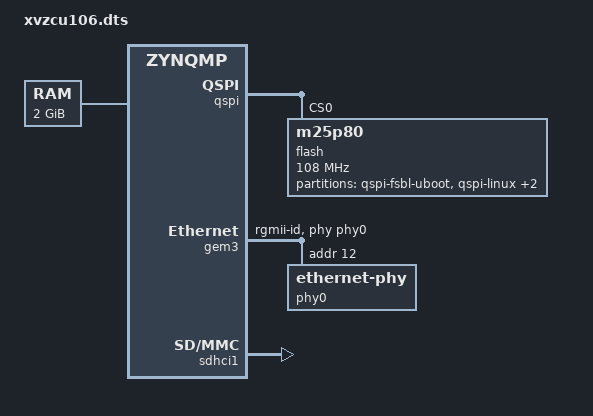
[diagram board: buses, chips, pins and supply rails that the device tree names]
/*
 * CAUTION: This file is automatically generated by Xilinx.
 * Version: XSCT 2020.1
 * Today is: Wed Dec 29 20:15:44 2021
 */

/dts-v1/;
#include "zynqmp.dtsi"
#include "zynqmp-clk-ccf.dtsi"
#include "pl.dtsi"
#include "pcw.dtsi"
/ {
	chosen {
		bootargs = " earlycon console=ttyPS0,115200 clk_ignore_unused";
		stdout-path = "serial0:115200n8";
	};
	aliases {
		ethernet0 = &gem3;
		i2c0 = &i2c0;
		i2c1 = &i2c1;
		serial0 = &uart0;
		serial1 = &uart1;
		spi0 = &qspi;
	};
	memory {
		device_type = "memory";
		reg = <0x0 0x0 0x0 0x7ff00000>;
	};
};


&qspi {
	status = "okay";
	is-dual = <1>;
	flash@0 {
		compatible = "m25p80", "jedec,spi-nor"; /* 32MB */
		#address-cells = <1>;
		#size-cells = <1>;
		reg = <0x0>;
		spi-tx-bus-width = <1>;
		spi-rx-bus-width = <4>; /* FIXME also DUAL configuration possible */
		spi-max-frequency = <108000000>; /* Based on DC1 spec */
		partition@0 { /* for testing purpose */
			label = "qspi-fsbl-uboot";
			reg = <0x0 0x100000>;
		};
		partition@100000 { /* for testing purpose */
			label = "qspi-linux";
			reg = <0x100000 0x500000>;
		};
		partition@600000 { /* for testing purpose */
			label = "qspi-device-tree";
			reg = <0x600000 0x20000>;
		};
		partition@620000 { /* for testing purpose */
			label = "qspi-rootfs";
			reg = <0x620000 0x5E0000>;
		};
	};
};

&gem3 {
	status = "okay";
	phy-handle = <&phy0>;
	phy-mode = "rgmii-id";
	phy0: ethernet-phy@c {
		reg = <0xc>;
		ti,rx-internal-delay = <0x8>;
		ti,tx-internal-delay = <0xa>;
		ti,fifo-depth = <0x1>;
		ti,dp83867-rxctrl-strap-quirk;
	};
};

&sdhci1 {
	status = "okay";
	/*
	 * This property should be removed for supporting UHS mode
	 */
	no-1-8-v;
	xlnx,mio_bank = <1>;
};

&uart1 {
	status = "disabled";
};
